VERSION ""

NS_ :

BS_:

BU_:

BO_ 3221225472 VECTOR__INDEPENDENT_SIG_MSG: 0 Vector__XXX
 SG_ Low_FlowRate : 0|8@1+ (1,0) [0|0] "" Vector__XXX

BO_ 912 HEARTBEAT: 8 Vector__XXX
 SG_ State : 0|8@1+ (1,0) [0|0] "" Vector__XXX
 SG_ Counter : 8|8@1+ (1,0) [0|0] "" Vector__XXX

BO_ 913 ERROR: 8 Vector__XXX

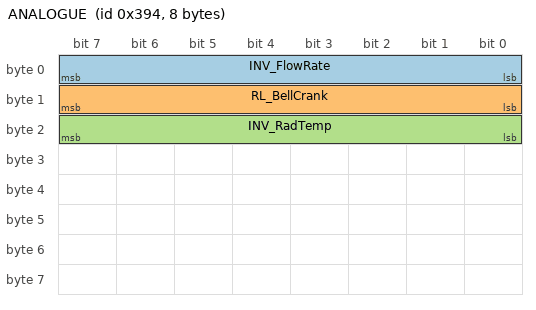
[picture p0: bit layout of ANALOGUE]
BO_ 916 ANALOGUE: 8 Vector__XXX
 SG_ INV_FlowRate : 0|8@1+ (1,0) [0|0] "" Vector__XXX
 SG_ RL_BellCrank : 8|8@1+ (1,0) [0|0] "" Vector__XXX
 SG_ INV_RadTemp : 16|8@1+ (1,0) [0|0] "" Vector__XXX
